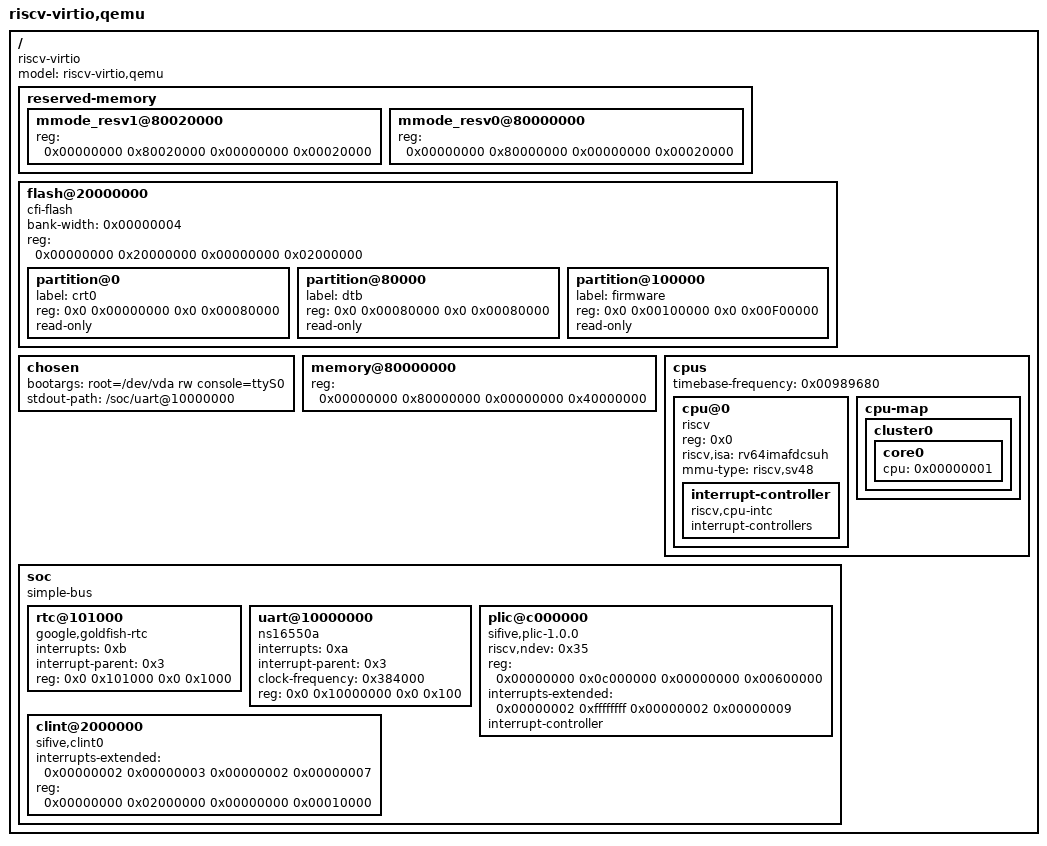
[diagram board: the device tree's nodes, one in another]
/dts-v1/;
/ {	
	#address-cells = <0x2>; 
	#size-cells = <0x2>;
	compatible = "riscv-virtio";
	model = "riscv-virtio,qemu";
	reserved-memory {
	    #address-cells = <0x00000002>;
	    #size-cells = <0x00000002>;
	    ranges;
	    mmode_resv1@80020000 {
		reg = <0x00000000 0x80020000 0x00000000 0x00020000>;
	    };
	    mmode_resv0@80000000 {
		reg = <0x00000000 0x80000000 0x00000000 0x00020000>;
	    };
	};
	flash@20000000 {
		bank-width = <0x00000004>;
		reg = <0x00000000 0x20000000 0x00000000 0x02000000>;
		compatible = "cfi-flash", "jedec-flash";
		partition@0 {
			label = "crt0";
			reg = <0x0 0x00000000 0x0 0x00080000>;
			read-only;
		};
		partition@80000 {
			label = "dtb";
			reg = <0x0 0x00080000 0x0 0x00080000>;
			read-only;
		};

		partition@100000 {
			label = "firmware";
			reg = <0x0 0x00100000 0x0 0x00F00000>;
			read-only;
		};
	};
	chosen {
		bootargs = "root=/dev/vda rw console=ttyS0";
		stdout-path = "/soc/uart@10000000";

	};
	memory@80000000 {
		device_type = "memory";
		reg = <0x00000000 0x80000000 0x00000000 0x40000000>;
	};
	cpus {
		#address-cells = <0x00000001>;
		#size-cells = <0x00000000>;
		//timebase-frequency = <10000000>;
		timebase-frequency = <0x00989680>;
		cpu@0{
			phandle=<0x1>;
			device_type = "cpu";
			reg = <0x0>;
			status = "okay";
			compatible = "riscv";
			riscv,isa = "rv64imafdcsuh";
			mmu-type = "riscv,sv48";
			interrupt-controller{
				#interrupt-cells=<0x1>;
				interrupt-controllers;
				compatible="riscv,cpu-intc";
				phandle=<0x2>;
			};
		};
		cpu-map {
			cluster0 {
				core0 {
					cpu = <0x00000001>;
				};
			};
		};

	};
	soc {
		#address-cells = <0x2>; 
		#size-cells = <0x2>;
		compatible = "simple-bus";
		ranges; 
		rtc@101000{
			interrupts = <0xb>;
			interrupt-parent = <0x3>;
			reg = <0x0 0x101000 0x0 0x1000>;
			compatible = "google,goldfish-rtc";
		};
		uart@10000000{
			interrupts = <0xa>;
			interrupt-parent = <0x3>;
			clock-frequency = <0x384000>;
			reg = <0x0 0x10000000 0x0 0x100>;
			compatible = "ns16550a";
		};
		plic@c000000 {
			phandle = <0x3>;
			riscv,ndev = <0x35>;
			reg = <0x00000000 0x0c000000 0x00000000 0x00600000>;
			interrupts-extended = <0x00000002 0xffffffff 0x00000002 0x00000009>;
			interrupt-controller;
			compatible = "sifive,plic-1.0.0", "riscv,plic0";
			#interrupt-cells = <0x1>;
		};
		clint@2000000 {
			interrupts-extended = <0x00000002 0x00000003 0x00000002 0x00000007>;
			reg = <0x00000000 0x02000000 0x00000000 0x00010000>;
			compatible = "sifive,clint0", "riscv,clint0";
		};


	};

};
